AUTOSAR XML (schema 4-0-3)
standard types defined: Boolean, UInt32
package /AUTOSAR_Platform/DataConstrs
  range DC_Boolean: raw 0..1
package /PATAC/MSM/ComponentTypes
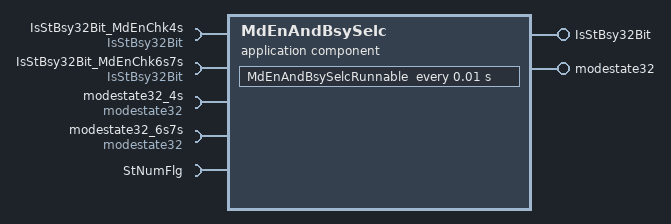
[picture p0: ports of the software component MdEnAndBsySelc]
  application sw component type MdEnAndBsySelc
    provide port IsStBsy32Bit: nonqueued-sender-com-spec{data-element=IsStBsy32Bit/Val, init-value=0}, provided-interface=IsStBsy32Bit
    provide port modestate32: nonqueued-sender-com-spec{data-element=modestate32/Val, init-value=0}, provided-interface=modestate32
    5 x require port:
      IsStBsy32Bit_MdEnChk4s: nonqueued-receiver-com-spec{data-element=IsStBsy32Bit/Val, filter=data-filter-type=ALWAYS, init-value=0}, required-interface=IsStBsy32Bit
      IsStBsy32Bit_MdEnChk6s7s: nonqueued-receiver-com-spec{data-element=IsStBsy32Bit/Val, filter=data-filter-type=ALWAYS, init-value=0}, required-interface=IsStBsy32Bit
      modestate32_4s: nonqueued-receiver-com-spec{data-element=modestate32/Val, filter=data-filter-type=ALWAYS, init-value=0}, required-interface=modestate32
      modestate32_6s7s: nonqueued-receiver-com-spec{data-element=modestate32/Val, filter=data-filter-type=ALWAYS, init-value=0}, required-interface=modestate32
      StNumFlg: required-interface=StNumFlg
        required-com-specs:
          data-element=Is4s, filter=data-filter-type=ALWAYS, init-value=0
          data-element=Is6s, filter=data-filter-type=ALWAYS, init-value=0
          data-element=Is6s7s, filter=data-filter-type=ALWAYS, init-value=0
          data-element=Is7s, filter=data-filter-type=ALWAYS, init-value=0
    behavior MdEnAndBsySelc_InternalBehavior
      timing event TMT_MdEnAndBsySelcRunnable: start-on-event=MdEnAndBsySelcRunnable, period=0.01
      runnable MdEnAndBsySelcRunnable
        data-receive-point-by-arguments:
          6 x access:
            REC_IsStBsy32Bit_MdEnChk4s_Val: accessed-variable=IsStBsy32Bit_MdEnChk4s.Val
            REC_IsStBsy32Bit_MdEnChk6s7s_Val: accessed-variable=IsStBsy32Bit_MdEnChk6s7s.Val
            REC_modestate32_4s_Val: accessed-variable=modestate32_4s.Val
            REC_modestate32_6s7s_Val: accessed-variable=modestate32_6s7s.Val
            REC_StNumFlg_Is4s: accessed-variable=StNumFlg.Is4s
            REC_StNumFlg_Is6s7s: accessed-variable=StNumFlg.Is6s7s
        data-send-points:
          access SEND_IsStBsy32Bit_Val: accessed-variable=IsStBsy32Bit.Val
          access SEND_modestate32_Val: accessed-variable=modestate32.Val
  swc implementation MdEnAndBsySelc_Implementation: behavior=MdEnAndBsySelc_InternalBehavior
    code-descriptors:
      code Default: artifact-descriptors=autosar-engineering-object={short-label=Default, category=SWSRC}
package /PATAC/MSM/ModeAdjust/PortInterface
  sender receiver interface IsStBsy32Bit: invalidation-policy{data-element=IsStBsy32Bit/Val, handle-invalid=DONT-INVALIDATE}
    data Val: type=UInt32
  sender receiver interface modestate32: invalidation-policy{data-element=modestate32/Val, handle-invalid=DONT-INVALIDATE}
    data Val: type=UInt32
  sender receiver interface StNumFlg
    4 x data, all with type=Boolean:
      Is4s
      Is6s
      Is6s7s
      Is7s
    invalidation-policys:
      data-element=Is7s, handle-invalid=DONT-INVALIDATE
      data-element=Is6s, handle-invalid=DONT-INVALIDATE
      data-element=Is4s, handle-invalid=DONT-INVALIDATE
      data-element=Is6s7s, handle-invalid=DONT-INVALIDATE
